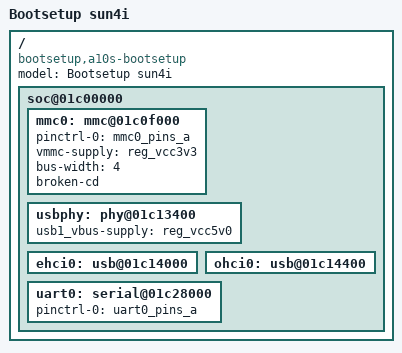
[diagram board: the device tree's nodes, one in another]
/*
 * Copyright 2013 Maxime Ripard
 *
 * Maxime Ripard <maxime.ripard@free-electrons.com>
 *
 * The code contained herein is licensed under the GNU General Public
 * License. You may obtain a copy of the GNU General Public License
 * Version 2 or later at the following locations:
 *
 * http://www.opensource.org/licenses/gpl-license.html
 * http://www.gnu.org/copyleft/gpl.html
 */

/dts-v1/;
/include/ "sun5i-a10s.dtsi"
/include/ "sunxi-common-regulators.dtsi"

/ {
	model = "Bootsetup sun4i";
	compatible = "bootsetup,a10s-bootsetup", "allwinner,sun5i-a10s";

	soc@01c00000 {
		mmc0: mmc@01c0f000 {
			pinctrl-names = "default";
			pinctrl-0 = <&mmc0_pins_a>;
			vmmc-supply = <&reg_vcc3v3>;
			bus-width = <4>;
			broken-cd;
			status = "okay";
		};

		usbphy: phy@01c13400 {
			usb1_vbus-supply = <&reg_vcc5v0>;
			status = "okay";
		};

		ehci0: usb@01c14000 {
			status = "okay";
		};

		ohci0: usb@01c14400 {
			status = "okay";
		};

		uart0: serial@01c28000 {
			pinctrl-names = "default";
			pinctrl-0 = <&uart0_pins_a>;
			status = "okay";
		};
	};
};
